# MB9AF42xL register map
File version: 1.0
Registers are 32-bit, read-write, reset 0x0 unless marked. A register's access mark holds for its fields unless they carry their own. Offsets are from the block's base; [hi:lo] are bit positions; {n}, {i} and the like mark numbered series; 'fields as' and 'values as' point back to an identical list.

## DAC — peripheral DAC
Base 0x40028000
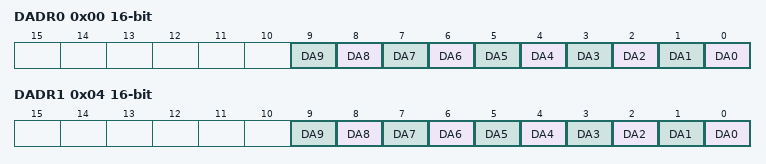
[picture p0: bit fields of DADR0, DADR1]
0x00 DADR0 16-bit reset not defined
  [n] DA{n} (n=0..9)
0x02 DACR0 8-bit reset not defined
  [0] DAE
0x04 DADR1 16-bit reset not defined
  [n] DA{n} (n=0..9)
0x06 DACR1 8-bit reset not defined
  [0] DAE

## EXTI — peripheral EXTI
Base 0x40030000
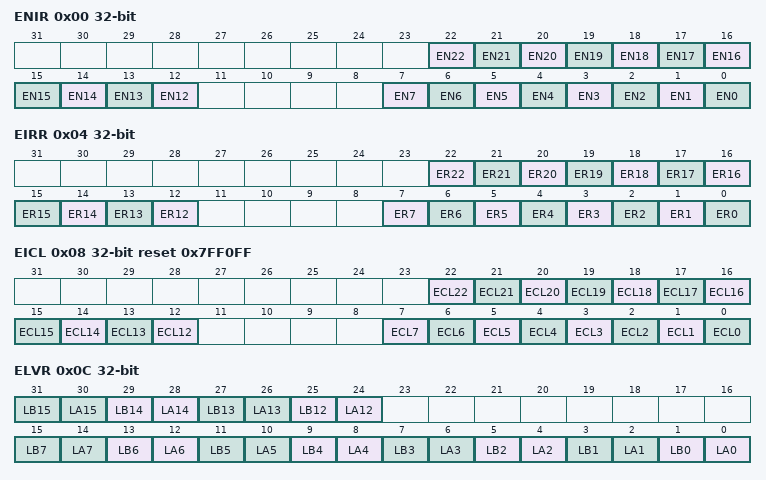
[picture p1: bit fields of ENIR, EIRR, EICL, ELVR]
0x00 ENIR
  [n] EN{n} (n=12..22), [n] EN{n} (n=0..7)
0x04 EIRR ro reset not defined
  [n] ER{n} rw (n=12..22), [n] ER{n} rw (n=0..7)
0x08 EICL reset 0x7FF0FF
  [n] ECL{n} (n=12..22), [n] ECL{n} (n=0..7)
0x0C ELVR
  [2n+1] LB{n} (n=12..15), [2n] LA{n} (n=12..15), [2n+1] LB{n} (n=0..7), [2n] LA{n} (n=0..7)
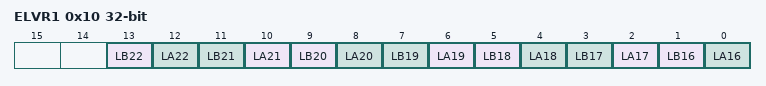
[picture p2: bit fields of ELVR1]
0x10 ELVR1
  [2n-31] LB{n} (n=16..22), [2n-32] LA{n} (n=16..22)
0x14 NMIRR 8-bit ro
  [0] NR
0x18 NMICL 8-bit reset 0x1
  [0] NCL

## INTREQ — peripheral INTREQ
Base 0x40031000
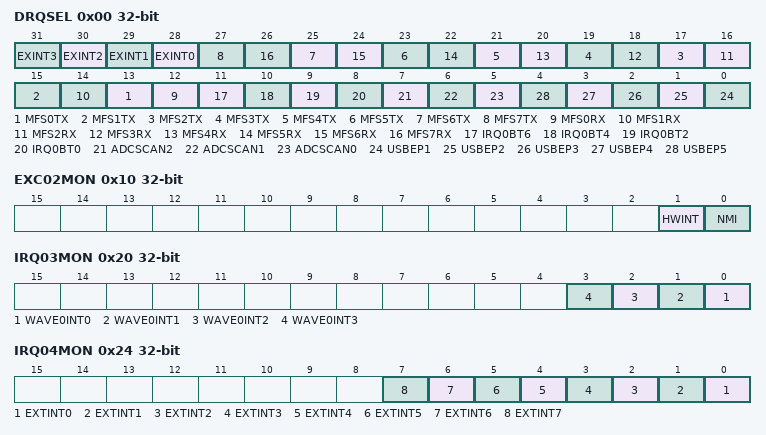
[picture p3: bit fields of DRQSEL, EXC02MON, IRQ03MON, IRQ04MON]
0x00 DRQSEL
  [n+28] EXINT{n} (n=0..3), [2n+13] MFS{n}TX (n=0..7), [2n+12] MFS{n}RX (n=0..7), [11] IRQ0BT6, [10] IRQ0BT4, [9] IRQ0BT2, [8] IRQ0BT0, [7] ADCSCAN2, [6] ADCSCAN1, [5] ADCSCAN0, [n-1] USBEP{n} (n=1..5)
0x0B ODDPKS 8-bit reset not defined
0x0C IRQCMODE
  [0] IRQCMODE
0x10 EXC02MON ro
  [1] HWINT, [0] NMI
0x14 IRQ00MON ro
  [0] FCSINT
0x18 IRQ01MON ro
  [0] SWWDTINT
0x1C IRQ02MON ro
  [0] LVDINT
0x20 IRQ03MON ro
  [n] WAVE0INT{n} (n=0..3)
0x24 IRQ04MON ro
  [n] EXTINT{n} (n=0..7)
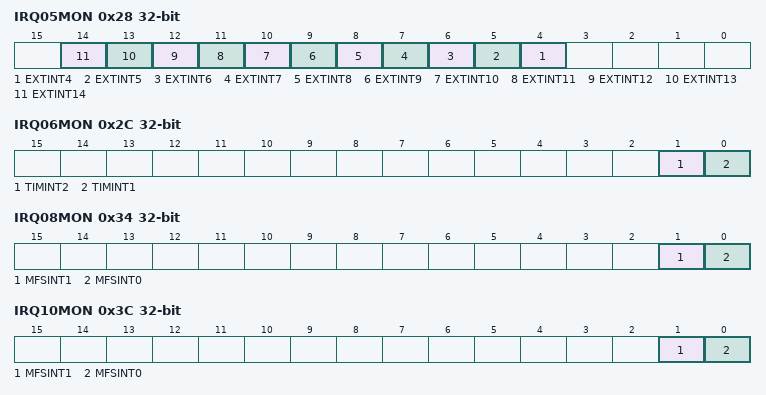
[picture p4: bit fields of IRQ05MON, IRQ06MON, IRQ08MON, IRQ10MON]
0x28 IRQ05MON ro
  [n] EXTINT{n} (n=4..14)
0x2C IRQ06MON ro
  [1] TIMINT2, [0] TIMINT1
0x30 IRQ07MON ro
  [0] MFSINT0
0x34 IRQ08MON ro
  [1] MFSINT1, [0] MFSINT0
0x38 IRQ09MON ro
  [0] MFSINT0
0x3C IRQ10MON ro
  [1] MFSINT1, [0] MFSINT0
0x40 IRQ11MON ro (reset mask 0x1)
0x44 IRQ12MON ro (reset mask 0x3)
0x48 IRQ13MON ro
  [0] MFSINT0
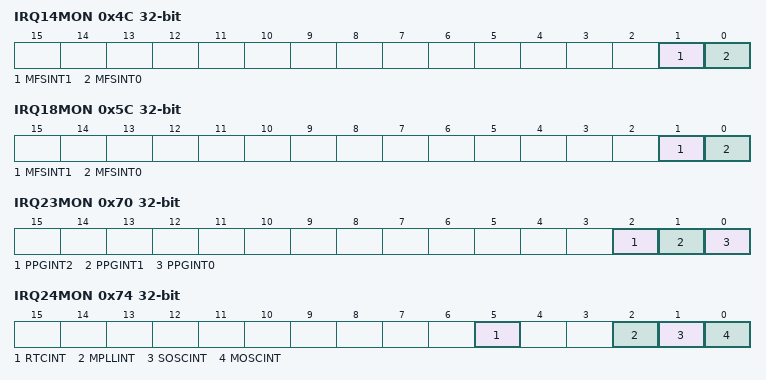
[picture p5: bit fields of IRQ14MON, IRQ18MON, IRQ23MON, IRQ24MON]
0x4C IRQ14MON ro
  [1] MFSINT1, [0] MFSINT0
0x50 IRQ15MON ro reset not defined
0x54 IRQ16MON ro reset not defined
0x58 IRQ17MON ro
  [0] MFSINT0
0x5C IRQ18MON ro
  [1] MFSINT1, [0] MFSINT0
{0x14+4i} IRQ{i}MON ro reset not defined (i=19..22)
0x70 IRQ23MON ro
  [2] PPGINT2, [1] PPGINT1, [0] PPGINT0
0x74 IRQ24MON ro
  [5] RTCINT, [2] MPLLINT, [1] SOSCINT, [0] MOSCINT
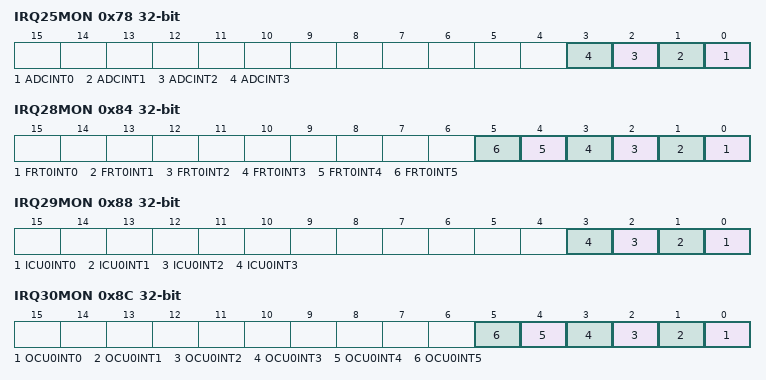
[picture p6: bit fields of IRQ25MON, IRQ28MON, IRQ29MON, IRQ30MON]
0x78 IRQ25MON ro
  [n] ADCINT{n} (n=0..3)
0x7C IRQ26MON ro reset not defined
0x80 IRQ27MON ro reset not defined
0x84 IRQ28MON ro
  [n] FRT0INT{n} (n=0..5)
0x88 IRQ29MON ro
  [n] ICU0INT{n} (n=0..3)
0x8C IRQ30MON ro reset not defined
  [n] OCU0INT{n} (n=0..5)
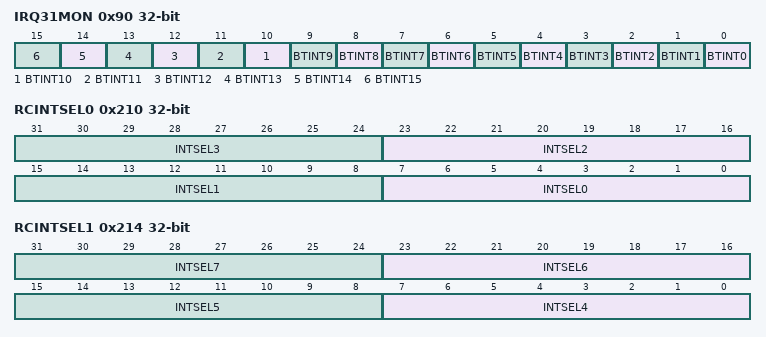
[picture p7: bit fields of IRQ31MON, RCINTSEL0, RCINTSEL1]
0x90 IRQ31MON ro
  [n] BTINT{n} (n=0..15)
0x94 IRQ32MON ro reset not defined
0x98 IRQ33MON ro
  [0] CAN1NT
{0x14+4i} IRQ{i}MON ro reset not defined (i=34..46)
0xD0 IRQ47MON ro
  [11] FLASHINT
0x210 RCINTSEL0
  [8n+7:8n] INTSEL{n} (n=0..3)
0x214 RCINTSEL1
  [8n-25:8n-32] INTSEL{n} (n=4..7)

## GPIO — peripheral GPIO
Base 0x40033000
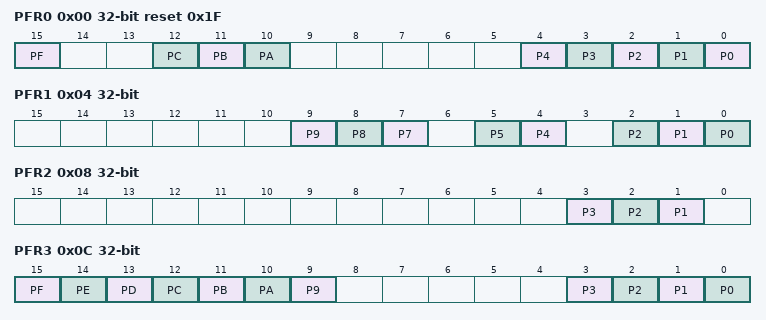
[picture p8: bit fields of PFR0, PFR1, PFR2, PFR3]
0x00 PFR0 reset 0x1F
  [15] PF, [12] PC, [11] PB, [10] PA, [n] P{n} (n=0..4)
0x04 PFR1 (reset mask 0x3BE)
  [9] P9, [8] P8, [7] P7, [5] P5, [4] P4, [2] P2, [1] P1, [0] P0
0x08 PFR2
  [3] P3, [2] P2, [1] P1
0x0C PFR3
  [15] PF, [14] PE, [13] PD, [12] PC, [11] PB, [10] PA, [9] P9, [n] P{n} (n=0..3)
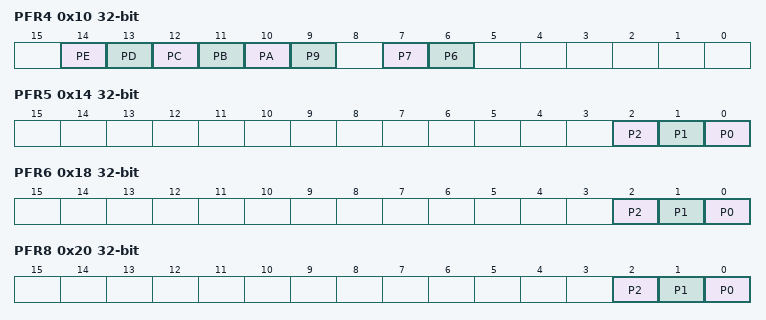
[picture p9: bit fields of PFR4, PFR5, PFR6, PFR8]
0x10 PFR4
  [14] PE, [13] PD, [12] PC, [11] PB, [10] PA, [9] P9, [7] P7, [6] P6
0x14 PFR5
  [2] P2, [1] P1, [0] P0
0x18 PFR6
  [2] P2, [1] P1, [0] P0
0x20 PFR8
  [2] P2, [1] P1, [0] P0
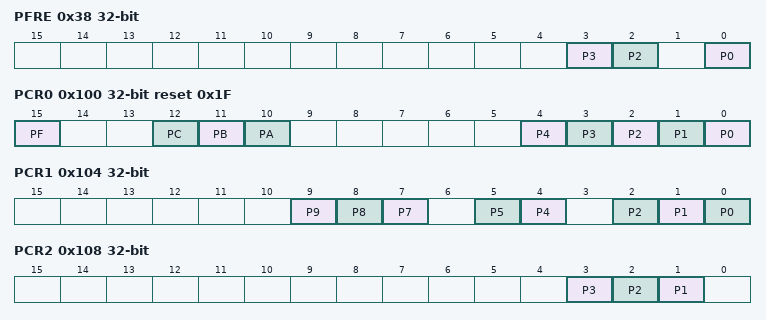
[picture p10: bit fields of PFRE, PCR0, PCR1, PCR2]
0x38 PFRE
  [3] P3, [2] P2, [0] P0
0x100 PCR0 reset 0x1F
  [15] PF, [12] PC, [11] PB, [10] PA, [n] P{n} (n=0..4)
0x104 PCR1 (reset mask 0x3BE)
  [9] P9, [8] P8, [7] P7, [5] P5, [4] P4, [2] P2, [1] P1, [0] P0
0x108 PCR2
  [3] P3, [2] P2, [1] P1
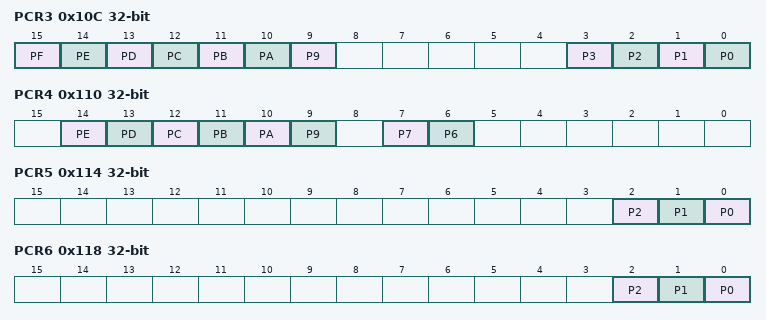
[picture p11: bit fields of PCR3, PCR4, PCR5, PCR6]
0x10C PCR3
  fields as PFR3
0x110 PCR4
  [14] PE, [13] PD, [12] PC, [11] PB, [10] PA, [9] P9, [7] P7, [6] P6
0x114 PCR5
  [2] P2, [1] P1, [0] P0
0x118 PCR6
  [2] P2, [1] P1, [0] P0
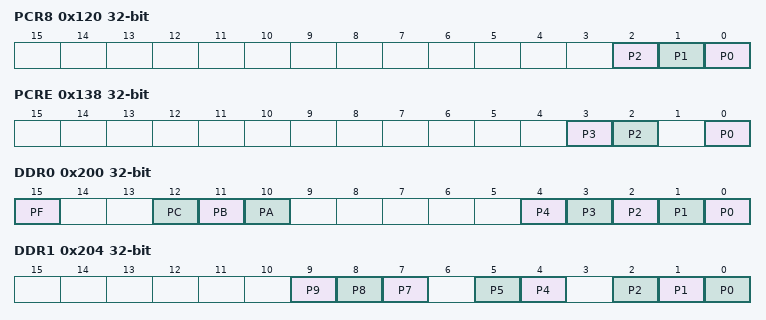
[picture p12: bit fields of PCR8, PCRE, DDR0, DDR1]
0x120 PCR8
  [2] P2, [1] P1, [0] P0
0x138 PCRE
  [3] P3, [2] P2, [0] P0
0x200 DDR0
  [15] PF, [12] PC, [11] PB, [10] PA, [n] P{n} (n=0..4)
0x204 DDR1 (reset mask 0x3BE)
  [9] P9, [8] P8, [7] P7, [5] P5, [4] P4, [2] P2, [1] P1, [0] P0
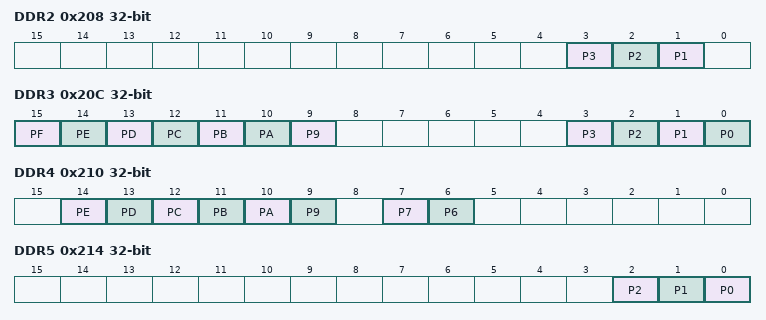
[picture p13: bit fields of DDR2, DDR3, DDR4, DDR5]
0x208 DDR2
  [3] P3, [2] P2, [1] P1
0x20C DDR3
  fields as PFR3
0x210 DDR4
  [14] PE, [13] PD, [12] PC, [11] PB, [10] PA, [9] P9, [7] P7, [6] P6
0x214 DDR5
  [2] P2, [1] P1, [0] P0
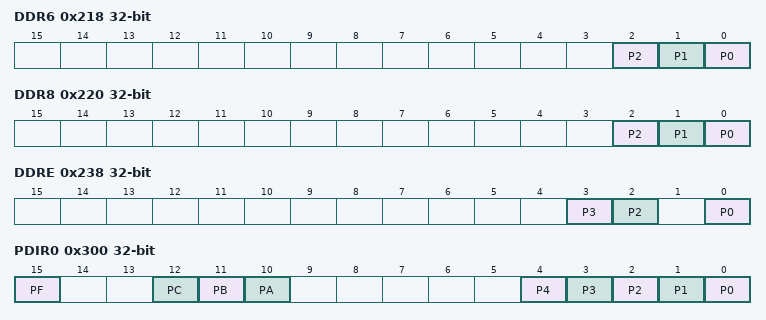
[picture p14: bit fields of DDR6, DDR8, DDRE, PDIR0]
0x218 DDR6
  [2] P2, [1] P1, [0] P0
0x220 DDR8
  [2] P2, [1] P1, [0] P0
0x238 DDRE
  [3] P3, [2] P2, [0] P0
0x300 PDIR0
  [15] PF, [12] PC, [11] PB, [10] PA, [n] P{n} (n=0..4)
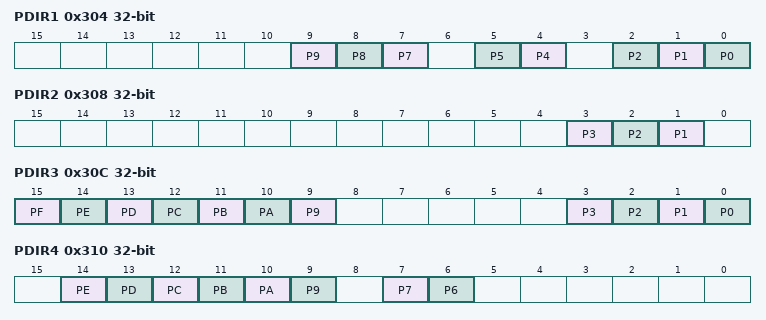
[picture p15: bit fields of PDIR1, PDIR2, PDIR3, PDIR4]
0x304 PDIR1 (reset mask 0x3BE)
  [9] P9, [8] P8, [7] P7, [5] P5, [4] P4, [2] P2, [1] P1, [0] P0
0x308 PDIR2
  [3] P3, [2] P2, [1] P1
0x30C PDIR3
  fields as PFR3
0x310 PDIR4
  [14] PE, [13] PD, [12] PC, [11] PB, [10] PA, [9] P9, [7] P7, [6] P6
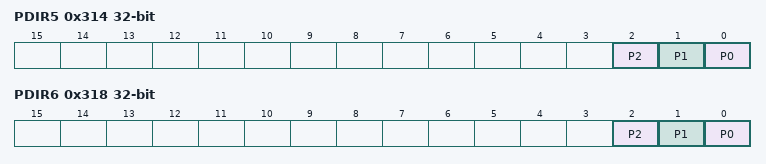
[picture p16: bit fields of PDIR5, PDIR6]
0x314 PDIR5
  [2] P2, [1] P1, [0] P0
0x318 PDIR6
  [2] P2, [1] P1, [0] P0
0x320 PDIR8
  [2] P2, [1] P1, [0] P0
0x338 PDIRE
  [3] P3, [2] P2, [0] P0
0x400 PDOR0
  [15] PF, [12] PC, [11] PB, [10] PA, [n] P{n} (n=0..4)
0x404 PDOR1 (reset mask 0x3BE)
  [9] P9, [8] P8, [7] P7, [5] P5, [4] P4, [2] P2, [1] P1, [0] P0
0x408 PDOR2
  [3] P3, [2] P2, [1] P1
0x40C PDOR3
  fields as PFR3
0x410 PDOR4
  [14] PE, [13] PD, [12] PC, [11] PB, [10] PA, [9] P9, [7] P7, [6] P6
0x414 PDOR5
  [2] P2, [1] P1, [0] P0
0x418 PDOR6
  [2] P2, [1] P1, [0] P0
0x420 PDOR8
  [2] P2, [1] P1, [0] P0
0x438 PDORE
  [3] P3, [2] P2, [0] P0
0x500 ADE reset 0x7037
  [14] AN14, [13] AN13, [12] AN12, [5] AN5, [4] AN4, [2] AN2, [1] AN1, [0] AN0
0x580 SPSR reset 0x5
  [3:2] MAINXC, [1:0] SUBXC
0x600 EPFR00 reset 0x30000
  [17] JTAGEN1S, [16] JTAGEN0B, [7:6] SUBOUTE, [5:4] RTCCOE, [2:1] CROUTE, [0] NMIS
0x604 EPFR01
  [3n+22:3n+20] IC{n:02}S (n=0..3), [19:18] FRCK0S, [17:16] DTTI0S, [12] DTTI0C, [2n+1:2n] RTO{n:02}E (n=0..5)
0x608 EPFR02 reset not defined
0x60C EPFR03 reset not defined
0x610 EPFR04
  [29:28] TIOB3S, [8n+3:8n+2] TIOA{n}E (n=0..3), [25:24] TIOA3S, [21:20] TIOB2S, [13:12] TIOB1S, [9:8] TIOA1S, [6:4] TIOB0S
0x614 EPFR05
  [8n-27:8n-28] TIOB{n}S (n=4..7), [8n-29:8n-30] TIOA{n}E (n=4..7), [25:24] TIOA7S, [9:8] TIOA5S
0x618 EPFR06
  [2n+1:2n] EINT{n}S (n=12..15), [2n+1:2n] EINT{n:02}S (n=0..7)
0x61C EPFR07
  [27:26] SCK3B, [25:24] SOT3B, [23:22] SIN3S, [15:14] SCK1B, [13:12] SOT1B, [11:10] SIN1S, [9:8] SCK0B, [7:6] SOT0B, [5:4] SIN0S
0x620 EPFR08
  [15:14] SCK5B, [13:12] SOT5B, [11:10] SIN5S
0x624 EPFR09
  [31:30] CTX1E, [29:28] CRX1S, [15:12] ADTRG0S
{0x600+4i} EPFR{i} reset not defined (i=10..14)
0x63C EPFR15
  [2n-31:2n-32] EINT{n}S (n=16..22)
{0x600+4i} EPFR{i} reset not defined (i=16..18)
0x708 PZR2
  [3] P3, [2] P2, [1] P1
0x714 PZR5
  [2] P2, [1] P1, [0] P0
0x718 PZR6
  [0] P0

## Notices in the file
Licence Terms
FUJITSU SEMICONDUCTOR LIMITED (gLICENSORh) hereby grants and
you (gLICENSEEh) hereby accept a non transferable, non-exclusive
licence to use and copy the deliverables (gDeliverablesh) solely for
the purpose of; (i) developing LICENSEEfs development tools and
distributing such development tools to third parties; (ii) generating
derivative representations of the Deliverables to develop and debug
software for LICENSORfs targeted devices or device series identified
within the Deliverables, (together the gPurposeh) under the following
terms and conditions:
1. Ownership.
The Deliverables are the property of LICENSOR. LICENSEE acquires no
right, title or interest in the Deliverables other than the licence
rights granted herein.
2. Use.
LICENSEE shall only be permitted to use the Deliverables for the
Purpose. LICENSEE shall not reverse engineer, decompile or
disassemble the Deliverables, in whole or in part.
3. Copies.
All copies of the Deliverables must bear the same notice(s) contained
on the original copies of the Deliverables.
4. No Warranty.
THE DELIVERABLES ARE PROVIDED gAS ISh AND ANY EXPRESS, IMPLIED OR
STATUTORY WARRANTIES, INCLUDING, BUT NOT LIMITED TO, THE IMPLIED
WARRANTIES OF MERCHANTABILITY, SATISFACTORY QUALITY AND FITNESS FOR
A PARTICULAR PURPOSE ARE DISCLAIMED.
IN NO EVENT SHALL LICENSOR BE LIABLE FOR ANY DIRECT, INDIRECT,
INCIDENTAL, SPECIAL, EXEMPLARY, OR CONSEQUENTIAL DAMAGES HOWEVER CAUSED
AND ON ANY THEORY OF LIABILITY, WHETHER IN CONTRACT, STRICT LIABILITY,
OR TORT (INCLUDING NEGLIGENCE OR OTHERWISE) ARISING IN ANY WAY OUT OF
THE USE OF THE DELIVERABLES, EVEN IF ADVISED OF THE POSSIBILITY OF SUCH
DAMAGE.
LICENSEE EXPRESSLY ASSUMES ALL LIABILITIES AND RISKS, FOR USE OR
OPERATION OF THE DELIVERABLES.
5.In the event that LICENSEE receives early access to the Deliverables,
LICENSEE acknowledges and agrees that;
(a) notwithstanding the licence grants above, LICENSEE shall only be
permitted to use the Deliverables solely internally for evaluation and
providing feedback to LICENSOR;
(b) except with respect to the limited licence grants in 5(a), LICENSEE
shall be subject to all of the terms and conditions set out above; and
(c) the Deliverables are confidential information and LICENSEE shall
maintain in confidence the Deliverables and apply security measures no
less stringent than the measures that LICENSEE applies to its own like
information, but not less than a reasonable degree of care, to prevent
unauthorised disclosure and use of the Deliverables.
